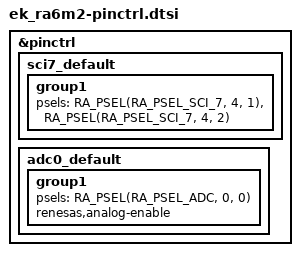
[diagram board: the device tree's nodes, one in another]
/*
 * Copyright (c) 2024 Renesas Electronics Corporation
 * SPDX-License-Identifier: Apache-2.0
 */

&pinctrl {
	sci7_default: sci7_default {
		group1 {
			/* tx rx */
			psels = <RA_PSEL(RA_PSEL_SCI_7, 4, 1)>,
			<RA_PSEL(RA_PSEL_SCI_7, 4, 2)>;
		};
	};

	adc0_default: adc0_default {
		group1 {
			/* input */
			psels = <RA_PSEL(RA_PSEL_ADC, 0, 0)>;
			renesas,analog-enable;
		};
	};
};
